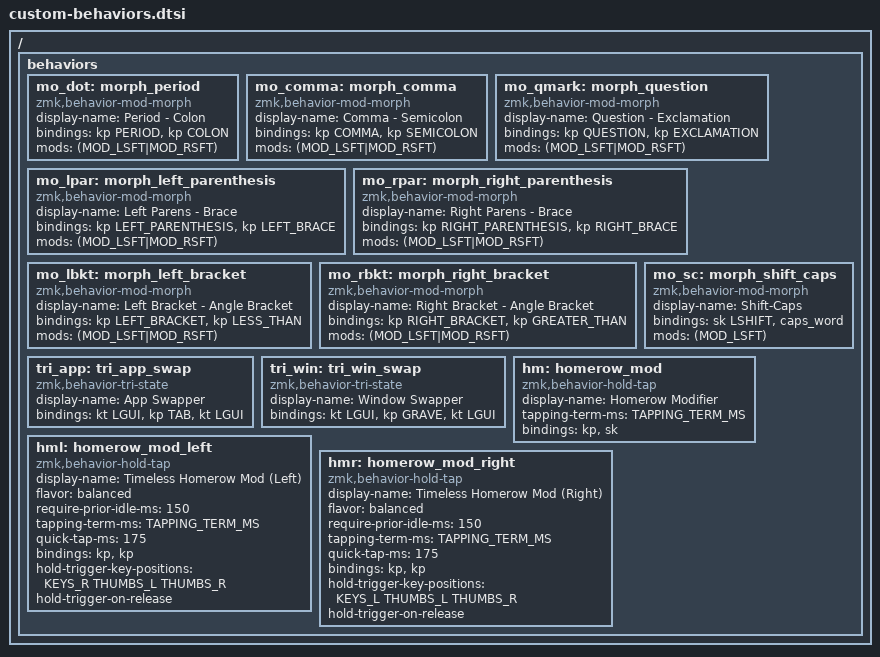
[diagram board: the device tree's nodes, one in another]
/ {
    behaviors {
        mo_dot: morph_period {
            compatible = "zmk,behavior-mod-morph";
            display-name = "Period - Colon";

            #binding-cells = <0>;
            bindings = <&kp PERIOD>, <&kp COLON>;
            mods = <(MOD_LSFT|MOD_RSFT)>;
        };

        mo_comma: morph_comma {
            compatible = "zmk,behavior-mod-morph";
            display-name = "Comma - Semicolon";

            #binding-cells = <0>;
            bindings = <&kp COMMA>, <&kp SEMICOLON>;
            mods = <(MOD_LSFT|MOD_RSFT)>;
        };

        mo_qmark: morph_question {
            compatible = "zmk,behavior-mod-morph";
            display-name = "Question - Exclamation";

            #binding-cells = <0>;
            bindings = <&kp QUESTION>, <&kp EXCLAMATION>;
            mods = <(MOD_LSFT|MOD_RSFT)>;
        };

        mo_lpar: morph_left_parenthesis {
            compatible = "zmk,behavior-mod-morph";
            display-name = "Left Parens - Brace";

            #binding-cells = <0>;
            bindings = <&kp LEFT_PARENTHESIS>, <&kp LEFT_BRACE>;
            mods = <(MOD_LSFT|MOD_RSFT)>;
        };

        mo_rpar: morph_right_parenthesis {
            compatible = "zmk,behavior-mod-morph";
            display-name = "Right Parens - Brace";

            #binding-cells = <0>;
            bindings = <&kp RIGHT_PARENTHESIS>, <&kp RIGHT_BRACE>;
            mods = <(MOD_LSFT|MOD_RSFT)>;
        };

        mo_lbkt: morph_left_bracket {
            compatible = "zmk,behavior-mod-morph";
            display-name = "Left Bracket - Angle Bracket";

            #binding-cells = <0>;
            bindings = <&kp LEFT_BRACKET>, <&kp LESS_THAN>;
            mods = <(MOD_LSFT|MOD_RSFT)>;
        };

        mo_rbkt: morph_right_bracket {
            compatible = "zmk,behavior-mod-morph";
            display-name = "Right Bracket - Angle Bracket";

            #binding-cells = <0>;
            bindings = <&kp RIGHT_BRACKET>, <&kp GREATER_THAN>;
            mods = <(MOD_LSFT|MOD_RSFT)>;
        };

        mo_sc: morph_shift_caps {
            compatible = "zmk,behavior-mod-morph";
            display-name = "Shift-Caps";

            #binding-cells = <0>;
            bindings = <&sk LSHIFT>, <&caps_word>;
            mods = <(MOD_LSFT)>;
        };

        tri_app: tri_app_swap {
            compatible = "zmk,behavior-tri-state";

            display-name = "App Swapper";
            #binding-cells = <0>;
            bindings = <&kt LGUI>, <&kp TAB>, <&kt LGUI>;
        };

        tri_win: tri_win_swap {
            compatible = "zmk,behavior-tri-state";

            display-name = "Window Swapper";
            #binding-cells = <0>;
            bindings = <&kt LGUI>, <&kp GRAVE>, <&kt LGUI>;
        };

        // Sticky when tapped but not when held
        hm: homerow_mod {
            compatible = "zmk,behavior-hold-tap";

            display-name = "Homerow Modifier";
            #binding-cells = <2>;
            tapping-term-ms = <TAPPING_TERM_MS>;
            bindings = <&kp>, <&sk>;
        };

        // urob's timeless
        // https://github.com/urob/zmk-config#timeless-homerow-mods
        hml: homerow_mod_left {
            compatible = "zmk,behavior-hold-tap";

            display-name = "Timeless Homerow Mod (Left)";
            #binding-cells = <2>;
            flavor = "balanced";
            require-prior-idle-ms = <150>;
            tapping-term-ms = <TAPPING_TERM_MS>;
            quick-tap-ms = <175>;
            bindings = <&kp>, <&kp>;
            hold-trigger-key-positions = < KEYS_R THUMBS_L THUMBS_R>;
            hold-trigger-on-release;
        };

        hmr: homerow_mod_right {
            compatible = "zmk,behavior-hold-tap";

            display-name = "Timeless Homerow Mod (Right)";
            #binding-cells = <2>;
            flavor = "balanced";
            require-prior-idle-ms = <150>;
            tapping-term-ms = <TAPPING_TERM_MS>;
            quick-tap-ms = <175>;
            bindings = <&kp>, <&kp>;
            hold-trigger-key-positions = < KEYS_L THUMBS_L THUMBS_R>;
            hold-trigger-on-release;
        };
    };
};
